# YTM32B1MD2 register map
Vendor: YTMicro; File version: 1.0
CPU: CM33 r0p4, little endian, MPU, FPU, 2 interrupt priority bits
Registers are 32-bit, read-write, reset 0x0 unless marked. A register's access mark holds for its fields unless they carry their own. Offsets are from the block's base; [hi:lo] are bit positions; {n}, {i} and the like mark numbered series.

## CIM — Chip Integration Module of Microcontroller
Base 0x4007B000; register names take the prefix CIM_
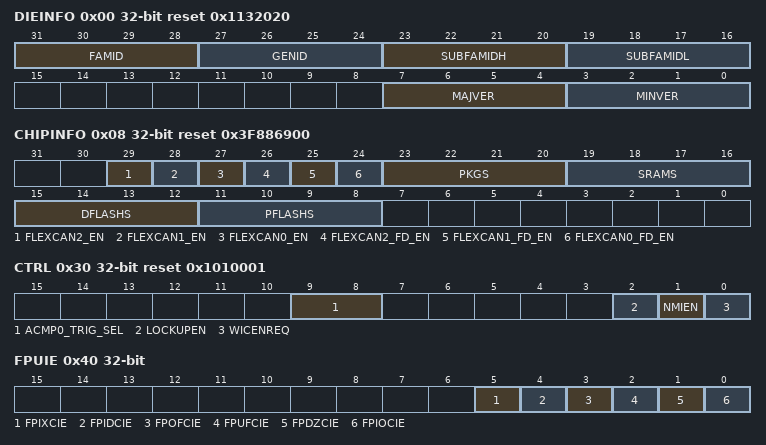
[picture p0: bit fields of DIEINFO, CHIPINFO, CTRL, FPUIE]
0x00 DIEINFO ro reset 0x1132020
  [31:28] FAMID — Describe the product family information.
    0=B - Basic(General); 1=D - Dashboard; 2=P - Powertrain; 3=V - Vision; 4=N - Networks
  [27:24] GENID — Describe the product generation information.
    1=1st generation production; 2=2nd generation production; 3=3rd generation production
  [23:20] SUBFAMIDH — Describe the product sub family information.
    0=L - Low end; 1=M - Middle end; 2=H - High end
  [19:16] SUBFAMIDL — Describe the product max Flash size information.
    0=A - 64KB; 1=B - 128KB; 2=C - 256KB; 3=D - 512KB; 4=E - 1MB
  [7:4] MAJVER — Describe the major version information.
  [3:0] MINVER — Describe the minor version information.
0x08 CHIPINFO ro reset 0x3F886900
  [29] FLEXCAN2_EN — FlexCAN2 Enable/Disable
    0=FlexCAN2 is disabled; 1=FlexCAN2 is enabled
  [28] FLEXCAN1_EN — FlexCAN1 Enable/Disable
    0=FlexCAN1 is disabled; 1=FlexCAN1 is enabled
  [27] FLEXCAN0_EN — FlexCAN0 Enable/Disable
    0=FlexCAN0 is disabled; 1=FlexCAN0 is enabled
  [26] FLEXCAN2_FD_EN — FlexCAN2 FD Feature Enable/Disable
    0=FlexCAN2 FD Feature is disabled; 1=FlexCAN2 FD Feature is enabled
  [25] FLEXCAN1_FD_EN — FlexCAN1 FD Feature Enable/Disable
    0=FlexCAN1 FD Feature is disabled; 1=FlexCAN1 FD Feature is enabled
  [24] FLEXCAN0_FD_EN — FlexCAN0 FD Feature Enable/Disable
    0=FlexCAN0 FD Feature is disabled; 1=FlexCAN0 FD Feature is enabled
  [23:20] PKGS — Describe chip package type information.
    3=48 LQFP; 4=64 LQFP; 8=100 LQFP
  [19:16] SRAMS — Describe sram size information.
    6=16KB; 7=32KB; 8=64KB
  [15:12] DFLASHS — Describe data Flash size information.
    4=16KB; 5=32KB; 6=64KB
  [11:8] PFLASHS — Describe program Flash size information.
    7=128KB; 8=256KB; 9=512KB
0x30 CTRL reset 0x1010001
  [9:8] ACMP0_TRIG_SEL — ACMP0 Trigger Select
    0=TMU output directly; 1=TMU output synced by bus clock; 2=TMU output synced by ACMP0 func clock
  [2] LOCKUPEN — Enable CPU Lockup Reset
    0=CPU Lockup reset is disabled; 1=CPU Lockup reset is enabled
  [1] NMIEN — Enable NMI function
    0=NMI is disabled; 1=NMI is enabled
  [0] WICENREQ — Enable WIC to wakeup low power mode.
    0=Disable WIC to wakeup low power mode; 1=Enable WIC to wakeup low power mode
0x40 FPUIE
  [all] fields
    0=Disable interrupt; 1=Enable interrupt
  [5] FPIXCIE
  [4] FPIDCIE
  [3] FPOFCIE
  [2] FPUFCIE
  [1] FPDZCIE
  [0] FPIOCIE
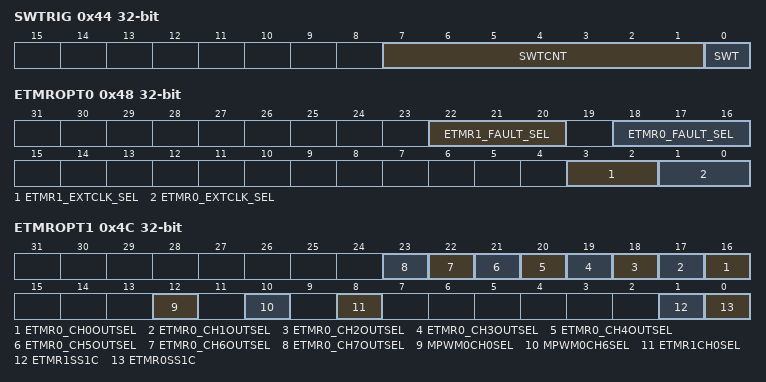
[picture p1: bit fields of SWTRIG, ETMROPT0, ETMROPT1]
0x44 SWTRIG
  [7:1] SWTCNT — Define software trigger valid length (multiplied with bus clock cycle), SWTCNT value will decrease until equal to zero when SWT set.
  [0] SWT — Generate software trigger.
    0=Software trigger is disabled; 1=Generate software trigger and it keeps until SWTCNT equals to zero
0x48 ETMROPT0
  [22:20] ETMR1_FAULT_SEL — Select fault source for eTMR1. xx0b - eTMR1 fault 0 input from pad. xx1b - eTMR1 fault 0 input from TMU. x0xb - eTMR1 fault 1 input from pad. x1xb - eTMR1 fault 1 input from TMU. 0xxb - eTMR1 fault 2 input from pad. 1xxb - eTMR1 fault 2 input from TMU.
  [18:16] ETMR0_FAULT_SEL — Select fault source for eTMR0. xx0b - eTMR0 fault 0 input from pad. xx1b - eTMR0 fault 0 input from TMU. x0xb - eTMR0 fault 1 input from pad. x1xb - eTMR0 fault 1 input from TMU. 0xxb - eTMR0 fault 2 input from pad. 1xxb - eTMR0 fault 2 input from TMU.
  [3:2] ETMR1_EXTCLK_SEL — Select external clock source for eTMR1.
    0=Select TCLK_IN0 input as external clock for eTMR1; 1=Select TCLK_IN1 input as external clock for eTMR1; 2=Select TCLK_IN2 input as external clock for eTMR1; 3=Select function clock from IPC
  [1:0] ETMR0_EXTCLK_SEL — Select external clock source for eTMR0.
    0=Select TCLK_IN0 input as external clock for eTMR0; 1=Select TCLK_IN1 input as external clock for eTMR0; 2=Select TCLK_IN2 input as external clock for eTMR0; 3=Select function clock from IPC
0x4C ETMROPT1
  [n+16] ETMR0_CH{n}OUTSEL (n=0..7) — Select modulation with eTMR1_CH1 for eTMR0 channel {n}.
    0=eTMR0 channel {n} output to pad directly; 1=eTMR0 channel {n} output modulation with eTMR1_CH1 output
  [12] MPWM0CH0SEL — Select input source for MPWM0 channel 0.
    0=MPWM0 channel 0 input from pad; 1=MPWM0 channel 0 input from XOR result(MPWM0_CH1, MPWM0_CH3, MPWM0_CH5)
  [10] MPWM0CH6SEL — Select input source for MPWM0 channel 6.
    0=MPWM0 channel 6 input from pad; 1=MPWM0 channel 6 input from ACMP out
  [8] ETMR1CH0SEL — Select input source for eTMR1 channel 0.
    0=eTMR1 channel 0 input from pad; 1=eTMR1 channel 0 input from ACMP out
  [1] ETMR1SS1C — Generate synchronize signal for eTMR1 trigger 1.
    0=Don't generate synchronize signal for eTMR1 trigger 1; 1=Generate synchronize signal for eTMR1 trigger 1
  [0] ETMR0SS1C — Generate synchronize signal for eTMR0 trigger 1.
    0=Don't generate synchronize signal for eTMR0 trigger 1; 1=Generate synchronize signal for eTMR0 trigger 1
